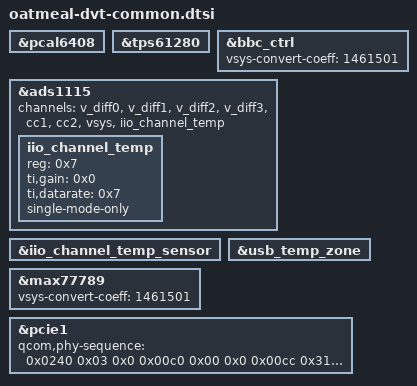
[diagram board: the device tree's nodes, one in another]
// SPDX-License-Identifier: GPL-2.0

#include "oatmeal.dtsi"

&pcal6408 {
	status = "ok";
};

&tps61280 {
	status = "ok";
};

&bbc_ctrl {
	/* vsys calculate:
	 * Radc and R768 are connected parallel,
	 * the paralleled resistor is named Rpara,
	 * then it in series with R767
	 * In DVT:
	 * R767=200Kohm, R768=453Kohm, Radc=10Mohm
	 * Rpara=R768*Radc/(R768+Radc)
	 *      =453K*10M/(453K+10M)
	 *      =433368ohm
	 * vsys = vsys_adc*(R767+Rpara)/Rpara
	 *      = vsys_adc*(200k+433368)/433368
	 *      = vsys_adc*1.461501
	 */
	vsys-convert-coeff = <1461501>;
	status = "ok";
};

&ads1115 {
	channels = "v_diff0",
		   "v_diff1",
		   "v_diff2",
		   "v_diff3",
		   "cc1",
		   "cc2",
		   "vsys",
		   "iio_channel_temp";

	iio_channel_temp {
		reg = <0x7>;
		ti,gain = <0x0>;
		ti,datarate = <0x7>;
		single-mode-only;
	};
};

&iio_channel_temp_sensor {
	io-channel-names = "iio_channel_temp";
	status = "ok";
};

&max77789 {
	vsys-convert-coeff = <1461501>;
};

&usb_temp_zone {
	status = "ok";
};

&pcie1 {
	// Override default QC config and use Separate Reference Clocks with
	// No SSC (SRNS). In this configuration, the refclk output is turned off
	qcom,phy-sequence = <0x0240 0x03 0x0
			0x00c0 0x00 0x0 // 0x00 - SSC off, 0x01 - SSC on
			0x00cc 0x31 0x0
			0x00d0 0x01 0x0
			0x0060 0xff 0x0
			0x0064 0x06 0x0
			0x0000 0x4c 0x0
			0x0004 0x06 0x0
			0x00f4 0x07 0x0
			0x0070 0x02 0x0
			0x0010 0x02 0x0
			0x0074 0x16 0x0
			0x0014 0x16 0x0
			0x0078 0x36 0x0
			0x0018 0x36 0x0
			0x0110 0x08 0x0
			0x00bc 0x0e 0x0
			0x0120 0x42 0x0
			0x0080 0x08 0x0
			0x0084 0x1a 0x0
			0x0020 0x14 0x0
			0x0024 0x34 0x0
			0x0088 0x82 0x0
			0x0028 0x68 0x0
			0x0090 0xab 0x0
			0x0094 0xea 0x0
			0x0098 0x02 0x0
			0x0030 0xab 0x0
			0x0034 0xaa 0x0
			0x0038 0x02 0x0
			0x0140 0x14 0x0
			0x0164 0x34 0x0
			0x003c 0x01 0x0
			0x001c 0x04 0x0
			0x0174 0x16 0x0
			0x01bc 0x0f 0x0
			0x0170 0xa0 0x0
			0x11a4 0x38 0x0
			0x10dc 0x11 0x0
			0x1160 0xbf 0x0
			0x1164 0xbf 0x0
			0x1168 0xb7 0x0
			0x116c 0xea 0x0
			0x115c 0x3f 0x0
			0x1174 0x5c 0x0
			0x1178 0x9c 0x0
			0x117c 0x1a 0x0
			0x1180 0x89 0x0
			0x1170 0xdc 0x0
			0x1188 0x94 0x0
			0x118c 0x5b 0x0
			0x1190 0x1a 0x0
			0x1194 0x89 0x0
			0x10cc 0x00 0x0
			0x1008 0x09 0x0
			0x1014 0x05 0x0
			0x1040 0x0f 0x0
			0x103c 0xff 0x0
			0x1030 0x2f 0x0
			0x1044 0x70 0x0
			0x1054 0x05 0x0
			0x1058 0x05 0x0
			0x104c 0x08 0x0
			0x1050 0x08 0x0
			0x10d8 0x0f 0x0
			0x1118 0x1c 0x0
			0x10f8 0x07 0x0
			0x11f8 0x08 0x0
			0x0e84 0x15 0x0
			0x0e90 0x3f 0x0
			0x0ee4 0x02 0x0
			0x0e40 0x06 0x0
			0x0e3c 0x18 0x0
			0x19a4 0x38 0x0
			0x18dc 0x11 0x0
			0x1960 0xbf 0x0
			0x1964 0xbf 0x0
			0x1968 0xb7 0x0
			0x196c 0xea 0x0
			0x195c 0x3f 0x0
			0x1974 0x5c 0x0
			0x1978 0x9c 0x0
			0x197c 0x1a 0x0
			0x1980 0x89 0x0
			0x1970 0xdc 0x0
			0x1988 0x94 0x0
			0x198c 0x5b 0x0
			0x1990 0x1a 0x0
			0x1994 0x89 0x0
			0x18cc 0x00 0x0
			0x1808 0x09 0x0
			0x1814 0x05 0x0
			0x1840 0x0f 0x0
			0x183c 0xff 0x0
			0x1830 0x2f 0x0
			0x1844 0x70 0x0
			0x1854 0x05 0x0
			0x1858 0x05 0x0
			0x184c 0x08 0x0
			0x1850 0x08 0x0
			0x18d8 0x0f 0x0
			0x1918 0x1c 0x0
			0x18f8 0x07 0x0
			0x19f8 0x08 0x0
			0x1600 0x00 0x0
			0x1684 0x15 0x0
			0x1690 0x3f 0x0
			0x16e4 0x02 0x0
			0x1640 0x06 0x0
			0x163c 0x18 0x0
			0x02c4 0xff 0x0
			0x02c8 0x89 0x0
			0x02dc 0x05 0x0
			0x0388 0x77 0x0
			0x0398 0x0b 0x0
			0x03c0 0x00 0x0
			0x03c4 0x28 0x0
			0x06a4 0x1e 0x0
			0x06f4 0x27 0x0
			0x03e0 0x0f 0x0
			0x060c 0x14 0x0
			0x0614 0x07 0x0
			0x061c 0x01 0x0
			0x0694 0x00 0x0
			0x03d0 0x8c 0x0
			0x0368 0x17 0x0
			0x1424 0x01 0x0
			0x1428 0x01 0x0
			0x0200 0x00 0x0
			0x0244 0x03 0x0
			0x0e14 0x26 0x0>;
};
